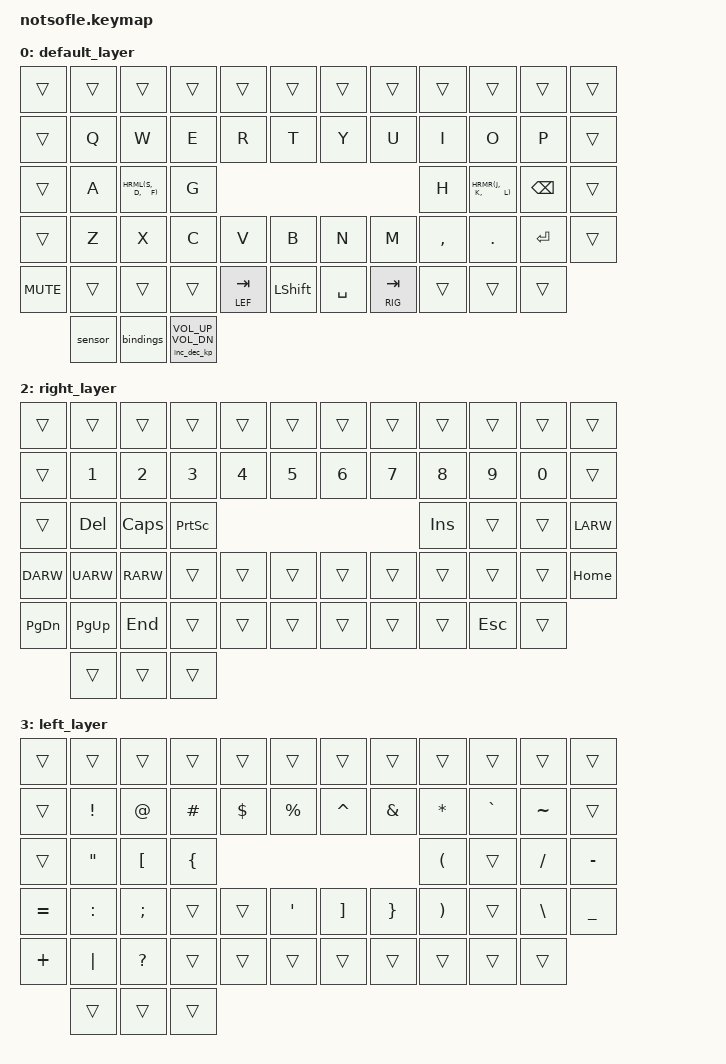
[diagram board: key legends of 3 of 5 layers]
#include <behaviors.dtsi>
#include <dt-bindings/zmk/bt.h>
#include <dt-bindings/zmk/keys.h>
#include <dt-bindings/zmk/mouse.h>
#include <dt-bindings/zmk/outputs.h>
#include <dt-bindings/zmk/rgb.h>

#include <input/processors.dtsi>

/*

   &mmv_input_listener {
       input-processors = <&zip_xy_scaler 2 1>;
   };

   &msc_input_listener {
       input-processors = <&zip_xy_scaler 2 1>;
   };

 */

#define ZMK_MOUSE_DEFAULT_MOVE_VAL 1200  // 600
#define ZMK_MOUSE_DEFAULT_SCRL_VAL 20    // 10

// Home row mods macro
#define HRML(k2,k3,k4) &ht LALT k2  &ht LCTRL k3  &ht LGUI k4
#define HRMR(k1,k2,k3) &ht RGUI k1  &ht RCTRL k2  &ht RALT k3
#define WHRML(k2,k3,k4) &ht LALT k2  &ht LGUI k3  &ht LCTRL k4
#define WHRMR(k1,k2,k3) &ht RCTRL k1  &ht RGUI k2  &ht RALT k3

#define MAC 0
#define WIN 1
#define RIG 2
#define LEF 3
#define TRI 4

/ {
    behaviors {
        mmv {
            acceleration-exponent = <1>;      // 1
            time-to-max-speed-ms = <900>;    // 40
            delay-ms = <0>;                   // 0
        };

        msc {
            acceleration-exponent = <1>;      // 0
            time-to-max-speed-ms = <400>;      // 500
            delay-ms = <0>;                   //   10
        };

        ht: hold_tap {
            label = "hold_tap";
            compatible = "zmk,behavior-hold-tap";
            #binding-cells = <2>;
            flavor = "tap-preferred";
            tapping-term-ms = <220>;
            quick-tap-ms = <150>;
            global-quick-tap;
            bindings = <&kp>, <&kp>;
        };
    };

    conditional_layers {
        compatible = "zmk,conditional-layers";
        tri_layer {
            if-layers = <RIG LEF>;
            then-layer = <TRI>;
        };
    };

    scroll_encoder: scroll_encoder {
        compatible = "zmk,behavior-sensor-rotate";
        #sensor-binding-cells = <0>;
        bindings = <&msc SCRL_DOWN>, <&msc SCRL_UP>;

        tap-ms = <30>;
    };

    keymap {
        compatible = "zmk,keymap";
        default_layer {
            bindings = <
&trans      &trans     &trans     &trans     &trans       &trans         &trans        &trans         &trans       &trans       &trans     &trans
&trans      &kp Q      &kp W      &kp E      &kp R        &kp T          &kp Y         &kp U          &kp I        &kp O        &kp P      &trans
&trans      &kp A     HRML(S,         D,     F)           &kp G          &kp H         HRMR(J,        K,           L)           &kp BSPC   &trans
&trans      &kp Z      &kp X      &kp C      &kp V        &kp B          &kp N         &kp M          &kp COMMA    &kp DOT      &kp ENTER  &trans
&kp C_MUTE  &trans     &trans     &trans     &lt LEF TAB  &kp LSHIFT     &kp SPACE     &lt RIG TAB    &trans       &trans       &trans

            sensor-bindings = <&inc_dec_kp C_VOLUME_UP C_VOL_DN>;
            >;
        };

        windows_layer {
            bindings = <
&trans      &trans     &trans     &trans     &trans       &trans         &trans        &trans          &trans       &trans       &trans     &trans
&trans      &kp Q      &kp W      &kp E      &kp R        &kp T          &kp Y         &kp U           &kp I        &kp O        &kp P      &trans
&trans      &kp A      WHRML(S,   D,         F)           &kp G          &kp H         WHRMR(J,        K,           L)           &kp BSPC   &trans
&trans      &kp Z      &kp X      &kp C      &kp V        &kp B          &kp N         &kp M           &kp COMMA    &kp DOT      &kp ENTER  &trans
&trans      &trans     &trans     &trans     &lt LEF TAB  &kp LSHIFT     &kp SPACE     &lt RIG TAB     &trans       &trans       &trans     
            >;
        };

        right_layer {
            bindings = <
&trans      &trans     &trans     &trans     &trans       &trans         &trans        &trans          &trans       &trans       &trans     &trans
&trans      &kp N1     &kp N2     &kp N3     &kp N4       &kp N5         &kp N6        &kp N7          &kp N8       &kp N9       &kp N0     &trans
&trans      &kp DEL    &kp CAPS   &kp PSCRN  &kp INS      &trans         &trans        &kp LARW        &kp DARW     &kp UARW     &kp RARW   &trans
&trans      &trans     &trans     &trans     &trans       &trans         &trans        &kp HOME        &kp PG_DN    &kp PG_UP    &kp END    &trans
&trans      &trans     &trans     &trans     &trans       &kp ESC        &trans        &trans          &trans       &trans
            >;
        };

        left_layer {
            bindings = <
&trans      &trans     &trans     &trans     &trans       &trans         &trans        &trans          &trans       &trans       &trans     &trans
&trans      &kp EXCL   &kp AT     &kp HASH   &kp DLLR     &kp PRCNT      &kp CARET     &kp AMPS        &kp ASTRK    &kp GRAVE    &kp TILDE  &trans
&trans      &kp DQT    &kp LBKT   &kp LBRC   &kp LPAR     &trans         &kp FSLH      &kp MINUS       &kp EQUAL    &kp COLON    &kp SEMI   &trans
&trans      &kp SQT    &kp RBKT   &kp RBRC   &kp RPAR     &trans         &kp BSLH      &kp UNDER       &kp PLUS     &kp PIPE     &kp QMARK  &trans
&trans      &trans     &trans     &trans     &trans       &trans         &trans        &trans          &trans       &trans
            >;
        };

        tri_layer {
            bindings = <
&trans      &trans     &trans     &trans     &trans       &trans         &trans        &trans         &trans       &trans        &trans       &trans
&trans      &kp F1     &kp F2     &kp F3     &kp F4       &bt BT_SEL 0   &bt BT_SEL 2  &out OUT_TOG   &tog WIN     &kp C_MUTE    &kp C_NEXT   &trans
&trans      &kp F5     &kp F6     &kp F7     &kp F8       &bt BT_SEL 1   &bt BT_SEL 3  &kp C_BRI_UP   &trans       &kp C_VOL_UP  &kp C_PP     &trans
&trans      &kp F9     &kp F10    &kp F11    &kp F12      &bt BT_CLR     &bt BT_SEL 4  &kp C_BRI_DEC  &trans       &kp C_VOL_DN  &kp C_PREV   &trans
&trans      &trans     &trans     &trans     &trans       &trans         &trans        &trans         &trans       &trans        &trans
            >;
        };
    };

};
